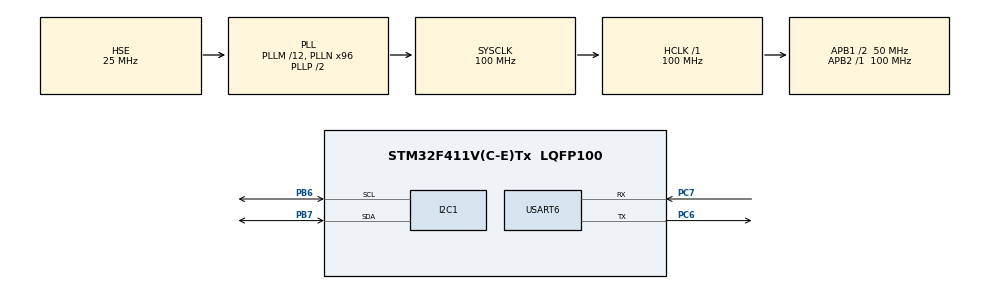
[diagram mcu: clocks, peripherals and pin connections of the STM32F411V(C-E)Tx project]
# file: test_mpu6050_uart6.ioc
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Dma.Request0=USART6_RX
Dma.Request1=USART6_TX
Dma.USART6_RX.0.Direction=DMA_PERIPH_TO_MEMORY
Dma.USART6_RX.0.FIFOMode=DMA_FIFOMODE_DISABLE
Dma.USART6_RX.0.Instance=DMA2_Stream1
Dma.USART6_RX.0.MemDataAlignment=DMA_MDATAALIGN_BYTE
Dma.USART6_RX.0.MemInc=DMA_MINC_ENABLE
Dma.USART6_RX.0.Mode=DMA_CIRCULAR
Dma.USART6_RX.0.PeriphDataAlignment=DMA_PDATAALIGN_BYTE
Dma.USART6_RX.0.PeriphInc=DMA_PINC_DISABLE
Dma.USART6_RX.0.Priority=DMA_PRIORITY_MEDIUM
Dma.USART6_TX.1.Direction=DMA_MEMORY_TO_PERIPH
Dma.USART6_TX.1.FIFOMode=DMA_FIFOMODE_DISABLE
Dma.USART6_TX.1.Instance=DMA2_Stream6
Dma.USART6_TX.1.MemDataAlignment=DMA_MDATAALIGN_BYTE
Dma.USART6_TX.1.MemInc=DMA_MINC_ENABLE
Dma.USART6_TX.1.Mode=DMA_NORMAL
Dma.USART6_TX.1.PeriphDataAlignment=DMA_PDATAALIGN_BYTE
Dma.USART6_TX.1.PeriphInc=DMA_PINC_DISABLE
Dma.USART6_TX.1.Priority=DMA_PRIORITY_MEDIUM
I2C1.I2C_Mode=I2C_Fast
Mcu.Family=STM32F4
Mcu.Name=STM32F411V(C-E)Tx
Mcu.Package=LQFP100
NVIC.DMA2_Stream1_IRQn=true\:0\:0\:false\:false\:true\:false\:true\:true
NVIC.DMA2_Stream6_IRQn=true\:0\:0\:false\:false\:true\:false\:true\:true
NVIC.PriorityGroup=NVIC_PRIORITYGROUP_4
NVIC.TIM2_IRQn=true\:0\:0\:false\:false\:true\:true\:true\:true
NVIC.USART6_IRQn=true\:0\:0\:false\:false\:true\:true\:true\:true
PA13.Mode=Serial_Wire
PA13.Signal=SYS_JTMS-SWDIO
PA14.Mode=Serial_Wire
PA14.Signal=SYS_JTCK-SWCLK
PB6.Mode=I2C
PB6.Signal=I2C1_SCL
PB7.Mode=I2C
PB7.Signal=I2C1_SDA
PC6.Mode=Asynchronous
PC6.Signal=USART6_TX
PC7.Mode=Asynchronous
PC7.Signal=USART6_RX
PH0\ -\ OSC_IN.Mode=HSE-External-Oscillator
PH0\ -\ OSC_IN.Signal=RCC_OSC_IN
PH1\ -\ OSC_OUT.Mode=HSE-External-Oscillator
PH1\ -\ OSC_OUT.Signal=RCC_OSC_OUT
ProjectManager.HeapSize=0x200
ProjectManager.StackSize=0x400
ProjectManager.TargetToolchain=MDK-ARM V5.32
RCC.48MHZClocksFreq_Value=50000000
RCC.AHBFreq_Value=100000000
RCC.APB1CLKDivider=RCC_HCLK_DIV2
RCC.APB1Freq_Value=50000000
RCC.APB1TimFreq_Value=100000000
RCC.APB2Freq_Value=100000000
RCC.APB2TimFreq_Value=100000000
RCC.CortexFreq_Value=100000000
RCC.HCLKFreq_Value=100000000
RCC.HSE_VALUE=25000000
RCC.HSI_VALUE=16000000
RCC.LSE_VALUE=32768
RCC.PLLM=12
RCC.PLLN=96
RCC.PLLSourceVirtual=RCC_PLLSOURCE_HSE
RCC.SYSCLKFreq_VALUE=100000000
RCC.SYSCLKSource=RCC_SYSCLKSOURCE_PLLCLK
RCC.VCOOutputFreq_Value=200000000
TIM2.AutoReloadPreload=TIM_AUTORELOAD_PRELOAD_ENABLE
TIM2.Period=10000-1
TIM2.Prescaler=100-1
USART6.VirtualMode=VM_ASYNC
VP_TIM2_VS_ClockSourceINT.Mode=Internal
board=custom

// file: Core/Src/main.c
/* USER CODE BEGIN Header */
/**
  ******************************************************************************
  * @file           : main.c
  * @brief          : Main program body
  ******************************************************************************
  * @attention
  *
  * Copyright (c) 2023 STMicroelectronics.
  * All rights reserved.
  *
  * This software is licensed under terms that can be found in the LICENSE file
  * in the root directory of this software component.
  * If no LICENSE file comes with this software, it is provided AS-IS.
  *
  ******************************************************************************
  */
/* USER CODE END Header */
#include "main.h"

/* USER CODE BEGIN Includes */
#include "MPU6050.h"
/* USER CODE END Includes */

/* USER CODE BEGIN PTD */
MPU6050_t MPU6050;

/* USER CODE END PTD */

I2C_HandleTypeDef hi2c1;

TIM_HandleTypeDef htim2;

UART_HandleTypeDef huart6;
DMA_HandleTypeDef hdma_usart6_rx;
DMA_HandleTypeDef hdma_usart6_tx;

void SystemClock_Config(void);
static void MX_GPIO_Init(void);
static void MX_DMA_Init(void);
static void MX_I2C1_Init(void);
static void MX_USART6_UART_Init(void);
static void MX_TIM2_Init(void);

int main(void)
{

  /* MCU Configuration--------------------------------------------------------*/

  /* Reset of all peripherals, Initializes the Flash interface and the Systick. */
  HAL_Init();

  /* Configure the system clock */
  SystemClock_Config();

  /* Initialize all configured peripherals */
  MX_GPIO_Init();
  MX_DMA_Init();
  MX_I2C1_Init();
  MX_USART6_UART_Init();
  MX_TIM2_Init();
	// Init MPU6050 and Timer 1 using gen 1ms -> update data
	MPU6050_Init();
	HAL_TIM_Base_Start_IT(&htim2);
	HAL_Delay(1000);

  /* Infinite loop */
  while (1)
  {

  }
}

void SystemClock_Config(void)
{
  RCC_OscInitTypeDef RCC_OscInitStruct = {0};
  RCC_ClkInitTypeDef RCC_ClkInitStruct = {0};

  /** Configure the main internal regulator output voltage
  */
  __HAL_RCC_PWR_CLK_ENABLE();
  __HAL_PWR_VOLTAGESCALING_CONFIG(PWR_REGULATOR_VOLTAGE_SCALE1);

  /** Initializes the RCC Oscillators according to the specified parameters
  * in the RCC_OscInitTypeDef structure.
  */
  RCC_OscInitStruct.OscillatorType = RCC_OSCILLATORTYPE_HSE;
  RCC_OscInitStruct.HSEState = RCC_HSE_ON;
  RCC_OscInitStruct.PLL.PLLState = RCC_PLL_ON;
  RCC_OscInitStruct.PLL.PLLSource = RCC_PLLSOURCE_HSE;
  RCC_OscInitStruct.PLL.PLLM = 12;
  RCC_OscInitStruct.PLL.PLLN = 96;
  RCC_OscInitStruct.PLL.PLLP = RCC_PLLP_DIV2;
  RCC_OscInitStruct.PLL.PLLQ = 4;
  if (HAL_RCC_OscConfig(&RCC_OscInitStruct) != HAL_OK)
  {
    Error_Handler();
  }

  /** Initializes the CPU, AHB and APB buses clocks
  */
  RCC_ClkInitStruct.ClockType = RCC_CLOCKTYPE_HCLK|RCC_CLOCKTYPE_SYSCLK
                              |RCC_CLOCKTYPE_PCLK1|RCC_CLOCKTYPE_PCLK2;
  RCC_ClkInitStruct.SYSCLKSource = RCC_SYSCLKSOURCE_PLLCLK;
  RCC_ClkInitStruct.AHBCLKDivider = RCC_SYSCLK_DIV1;
  RCC_ClkInitStruct.APB1CLKDivider = RCC_HCLK_DIV2;
  RCC_ClkInitStruct.APB2CLKDivider = RCC_HCLK_DIV1;

  if (HAL_RCC_ClockConfig(&RCC_ClkInitStruct, FLASH_LATENCY_3) != HAL_OK)
  {
    Error_Handler();
  }
}

static void MX_I2C1_Init(void)
{

  hi2c1.Instance = I2C1;
  hi2c1.Init.ClockSpeed = 400000;
  hi2c1.Init.DutyCycle = I2C_DUTYCYCLE_2;
  hi2c1.Init.OwnAddress1 = 0;
  hi2c1.Init.AddressingMode = I2C_ADDRESSINGMODE_7BIT;
  hi2c1.Init.DualAddressMode = I2C_DUALADDRESS_DISABLE;
  hi2c1.Init.OwnAddress2 = 0;
  hi2c1.Init.GeneralCallMode = I2C_GENERALCALL_DISABLE;
  hi2c1.Init.NoStretchMode = I2C_NOSTRETCH_DISABLE;
  if (HAL_I2C_Init(&hi2c1) != HAL_OK)
  {
    Error_Handler();
  }

}

static void MX_TIM2_Init(void)
{

  TIM_ClockConfigTypeDef sClockSourceConfig = {0};
  TIM_MasterConfigTypeDef sMasterConfig = {0};

  htim2.Instance = TIM2; // 1ms
  htim2.Init.Prescaler = 100-1;
  htim2.Init.CounterMode = TIM_COUNTERMODE_UP;
  htim2.Init.Period = 10000-1;
  htim2.Init.ClockDivision = TIM_CLOCKDIVISION_DIV1;
  htim2.Init.AutoReloadPreload = TIM_AUTORELOAD_PRELOAD_ENABLE;
  if (HAL_TIM_Base_Init(&htim2) != HAL_OK)
  {
    Error_Handler();
  }
  sClockSourceConfig.ClockSource = TIM_CLOCKSOURCE_INTERNAL;
  if (HAL_TIM_ConfigClockSource(&htim2, &sClockSourceConfig) != HAL_OK)
  {
    Error_Handler();
  }
  sMasterConfig.MasterOutputTrigger = TIM_TRGO_RESET;
  sMasterConfig.MasterSlaveMode = TIM_MASTERSLAVEMODE_DISABLE;
  if (HAL_TIMEx_MasterConfigSynchronization(&htim2, &sMasterConfig) != HAL_OK)
  {
    Error_Handler();
  }

}

static void MX_USART6_UART_Init(void)
{

  huart6.Instance = USART6;
  huart6.Init.BaudRate = 115200;
  huart6.Init.WordLength = UART_WORDLENGTH_8B;
  huart6.Init.StopBits = UART_STOPBITS_1;
  huart6.Init.Parity = UART_PARITY_NONE;
  huart6.Init.Mode = UART_MODE_TX_RX;
  huart6.Init.HwFlowCtl = UART_HWCONTROL_NONE;
  huart6.Init.OverSampling = UART_OVERSAMPLING_16;
  if (HAL_UART_Init(&huart6) != HAL_OK)
  {
    Error_Handler();
  }

}

static void MX_DMA_Init(void)
{

  /* DMA controller clock enable */
  __HAL_RCC_DMA2_CLK_ENABLE();

  /* DMA interrupt init */
  /* DMA2_Stream1_IRQn interrupt configuration */
  HAL_NVIC_SetPriority(DMA2_Stream1_IRQn, 0, 0);
  HAL_NVIC_EnableIRQ(DMA2_Stream1_IRQn);
  /* DMA2_Stream6_IRQn interrupt configuration */
  HAL_NVIC_SetPriority(DMA2_Stream6_IRQn, 0, 0);
  HAL_NVIC_EnableIRQ(DMA2_Stream6_IRQn);

}

static void MX_GPIO_Init(void)
{

  /* GPIO Ports Clock Enable */
  __HAL_RCC_GPIOH_CLK_ENABLE();
  __HAL_RCC_GPIOC_CLK_ENABLE();
  __HAL_RCC_GPIOA_CLK_ENABLE();
  __HAL_RCC_GPIOB_CLK_ENABLE();

}

/* USER CODE BEGIN 4 */
void HAL_TIM_PeriodElapsedCallback(TIM_HandleTypeDef *htim){
	// 1ms -> xay ra ngat, doc du lieu mpu6050
	if (htim->Instance == TIM2)
    {
        // Read sensor data from MPU6050
        //MPU6050_Read_Angle(&Angle);
        // Perform calculations to obtain roll, pitch, and yaw angles
        // ...
				MPU6050_Read_All(&MPU6050);
    }
}
/* USER CODE END 4 */

void Error_Handler(void)
{
  __disable_irq();
  while (1)
  {
  }
}
